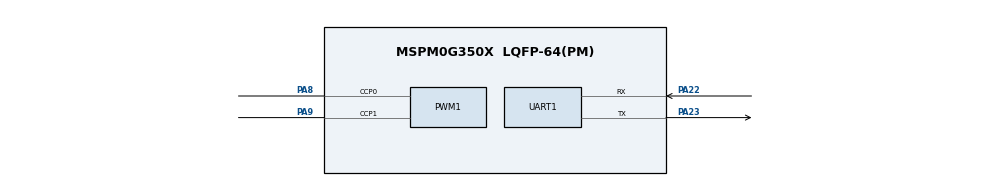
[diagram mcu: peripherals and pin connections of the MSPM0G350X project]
/**
 * @cliArgs --device "MSPM0G350X" --part "Default" --package "LQFP-64(PM)" --product "mspm0_sdk@2.10.00.04"
 * @versions {"tool":"1.26.2+4477"}
 */

/**
 * Import the modules used in this configuration.
 */
const GPIO   = scripting.addModule("/ti/driverlib/GPIO", {}, false);
const GPIO1  = GPIO.addInstance();
const GPIO2  = GPIO.addInstance();
const GPIO3  = GPIO.addInstance();
const GPIO4  = GPIO.addInstance();
const GPIO5  = GPIO.addInstance();
const GPIO6  = GPIO.addInstance();
const GPIO7  = GPIO.addInstance();
const GPIO8  = GPIO.addInstance();
const GPIO9  = GPIO.addInstance();
const GPIO10 = GPIO.addInstance();
const GPIO11 = GPIO.addInstance();
const GPIO12 = GPIO.addInstance();
const GPIO13 = GPIO.addInstance();
const GPIO14 = GPIO.addInstance();
const GPIO15 = GPIO.addInstance();
const GPIO16 = GPIO.addInstance();
const GPIO17 = GPIO.addInstance();
const GPIO18 = GPIO.addInstance();
const GPIO19 = GPIO.addInstance();
const GPIO20 = GPIO.addInstance();
const GPIO21 = GPIO.addInstance();
const PWM    = scripting.addModule("/ti/driverlib/PWM", {}, false);
const PWM1   = PWM.addInstance();
const SYSCTL = scripting.addModule("/ti/driverlib/SYSCTL");
const UART   = scripting.addModule("/ti/driverlib/UART", {}, false);
const UART1  = UART.addInstance();

/**
 * Write custom configuration values to the imported modules.
 */
GPIO1.$name                         = "GPIO_GRP_0";
GPIO1.port                          = "PORTB";
GPIO1.associatedPins[0].$name       = "PIN_2";
GPIO1.associatedPins[0].assignedPin = "2";

const Board = scripting.addModule("/ti/driverlib/Board", {}, false);

GPIO2.$name                         = "GPIO_GRP_1";
GPIO2.port                          = "PORTB";
GPIO2.associatedPins[0].$name       = "PIN_3";
GPIO2.associatedPins[0].assignedPin = "3";

GPIO3.$name                         = "GPIO_GRP_2";
GPIO3.port                          = "PORTB";
GPIO3.associatedPins[0].$name       = "PIN_6";
GPIO3.associatedPins[0].assignedPin = "6";

GPIO4.$name                         = "GPIO_GRP_3";
GPIO4.port                          = "PORTB";
GPIO4.associatedPins[0].$name       = "PIN_7";
GPIO4.associatedPins[0].assignedPin = "7";

GPIO5.port                          = "PORTA";
GPIO5.$name                         = "ENCODER_LEFTA";
GPIO5.associatedPins[0].direction   = "INPUT";
GPIO5.associatedPins[0].$name       = "PIN_0";
GPIO5.associatedPins[0].assignedPin = "0";
GPIO5.associatedPins[0].interruptEn = true;
GPIO5.associatedPins[0].polarity    = "RISE";

GPIO6.port                          = "PORTA";
GPIO6.$name                         = "ENCODER_LEFTB";
GPIO6.associatedPins[0].$name       = "PIN_1";
GPIO6.associatedPins[0].assignedPin = "1";
GPIO6.associatedPins[0].direction   = "INPUT";

GPIO7.port                          = "PORTA";
GPIO7.$name                         = "ENCODER_RIGHTA";
GPIO7.associatedPins[0].$name       = "PIN_26";
GPIO7.associatedPins[0].direction   = "INPUT";
GPIO7.associatedPins[0].interruptEn = true;
GPIO7.associatedPins[0].polarity    = "RISE";
GPIO7.associatedPins[0].assignedPin = "26";

GPIO8.port                          = "PORTA";
GPIO8.$name                         = "ENCODER_RIGHTB";
GPIO8.associatedPins[0].$name       = "PIN_27";
GPIO8.associatedPins[0].direction   = "INPUT";
GPIO8.associatedPins[0].assignedPin = "27";

GPIO9.port                          = "PORTB";
GPIO9.$name                         = "GRAY_L3";
GPIO9.associatedPins[0].direction   = "INPUT";
GPIO9.associatedPins[0].$name       = "PIN_24";
GPIO9.associatedPins[0].assignedPin = "24";

GPIO10.$name                         = "GRAY_L2";
GPIO10.port                          = "PORTB";
GPIO10.associatedPins[0].direction   = "INPUT";
GPIO10.associatedPins[0].$name       = "PIN_20";
GPIO10.associatedPins[0].assignedPin = "20";

GPIO11.$name                         = "GRAY_L1";
GPIO11.port                          = "PORTB";
GPIO11.associatedPins[0].direction   = "INPUT";
GPIO11.associatedPins[0].assignedPin = "19";
GPIO11.associatedPins[0].$name       = "PIN_19";

GPIO12.$name                         = "GRAY_M";
GPIO12.port                          = "PORTB";
GPIO12.associatedPins[0].$name       = "PIN_18";
GPIO12.associatedPins[0].assignedPin = "18";
GPIO12.associatedPins[0].direction   = "INPUT";

GPIO13.$name                          = "LED";
GPIO13.port                           = "PORTA";
GPIO13.associatedPins[0].$name        = "PIN_12";
GPIO13.associatedPins[0].assignedPin  = "12";
GPIO13.associatedPins[0].initialValue = "SET";

GPIO14.port                           = "PORTA";
GPIO14.$name                          = "BUZZER";
GPIO14.associatedPins[0].$name        = "PIN_13";
GPIO14.associatedPins[0].assignedPin  = "13";
GPIO14.associatedPins[0].initialValue = "SET";

GPIO15.$name                         = "GRAY_R1";
GPIO15.port                          = "PORTA";
GPIO15.associatedPins[0].assignedPin = "18";
GPIO15.associatedPins[0].$name       = "PINA_18";
GPIO15.associatedPins[0].direction   = "INPUT";

GPIO16.$name                         = "GRAY_R2";
GPIO16.port                          = "PORTA";
GPIO16.associatedPins[0].$name       = "PIN_17";
GPIO16.associatedPins[0].direction   = "INPUT";
GPIO16.associatedPins[0].assignedPin = "17";

GPIO17.$name                         = "GRAY_R3";
GPIO17.port                          = "PORTA";
GPIO17.associatedPins[0].$name       = "PIN_16";
GPIO17.associatedPins[0].direction   = "INPUT";
GPIO17.associatedPins[0].assignedPin = "16";

GPIO18.$name                              = "KEY1";
GPIO18.port                               = "PORTA";
GPIO18.associatedPins[0].direction        = "INPUT";
GPIO18.associatedPins[0].$name            = "PIN_21";
GPIO18.associatedPins[0].assignedPin      = "21";
GPIO18.associatedPins[0].internalResistor = "PULL_UP";

GPIO19.$name                              = "KEY2";
GPIO19.port                               = "PORTA";
GPIO19.associatedPins[0].direction        = "INPUT";
GPIO19.associatedPins[0].internalResistor = "PULL_UP";
GPIO19.associatedPins[0].assignedPin      = "24";
GPIO19.associatedPins[0].$name            = "PINA_24";

GPIO20.$name                              = "KEY3";
GPIO20.port                               = "PORTA";
GPIO20.associatedPins[0].direction        = "INPUT";
GPIO20.associatedPins[0].$name            = "PIN_02";
GPIO20.associatedPins[0].assignedPin      = "02";
GPIO20.associatedPins[0].internalResistor = "PULL_DOWN";

GPIO21.$name                         = "KEY4";
GPIO21.port                          = "PORTA";
GPIO21.associatedPins[0].direction   = "INPUT";
GPIO21.associatedPins[0].$name       = "PIN_28";
GPIO21.associatedPins[0].assignedPin = "28";

PWM1.$name                      = "PWM_0";
PWM1.peripheral.ccp0Pin.$assign = "PA8";
PWM1.peripheral.ccp1Pin.$assign = "PA9";
PWM1.PWM_CHANNEL_0.$name        = "ti_driverlib_pwm_PWMTimerCC0";
PWM1.PWM_CHANNEL_1.$name        = "ti_driverlib_pwm_PWMTimerCC1";
PWM1.ccp0PinConfig.$name        = "ti_driverlib_gpio_GPIOPinGeneric0";
PWM1.ccp1PinConfig.$name        = "ti_driverlib_gpio_GPIOPinGeneric1";

SYSCTL.forceDefaultClkConfig = true;

UART1.$name                            = "UART_2";
UART1.targetBaudRate                   = 115200;
UART1.peripheral.rxPin.$assign         = "PA22";
UART1.peripheral.txPin.$assign         = "PA23";
UART1.txPinConfig.$name                = "ti_driverlib_gpio_GPIOPinGeneric2";
UART1.txPinConfig.direction            = scripting.forceWrite("OUTPUT");
UART1.txPinConfig.hideOutputInversion  = scripting.forceWrite(false);
UART1.txPinConfig.onlyInternalResistor = scripting.forceWrite(false);
UART1.txPinConfig.passedPeripheralType = scripting.forceWrite("Digital");
UART1.rxPinConfig.$name                = "ti_driverlib_gpio_GPIOPinGeneric3";
UART1.rxPinConfig.hideOutputInversion  = scripting.forceWrite(false);
UART1.rxPinConfig.onlyInternalResistor = scripting.forceWrite(false);
UART1.rxPinConfig.passedPeripheralType = scripting.forceWrite("Digital");

/**
 * Pinmux solution for unlocked pins/peripherals. This ensures that minor changes to the automatic solver in a future
 * version of the tool will not impact the pinmux you originally saw.  These lines can be completely deleted in order to
 * re-solve from scratch.
 */
GPIO1.associatedPins[0].pin.$suggestSolution  = "PB2";
Board.peripheral.$suggestSolution             = "DEBUGSS";
Board.peripheral.swclkPin.$suggestSolution    = "PA20";
Board.peripheral.swdioPin.$suggestSolution    = "PA19";
GPIO2.associatedPins[0].pin.$suggestSolution  = "PB3";
GPIO3.associatedPins[0].pin.$suggestSolution  = "PB6";
GPIO4.associatedPins[0].pin.$suggestSolution  = "PB7";
GPIO5.associatedPins[0].pin.$suggestSolution  = "PA0";
GPIO6.associatedPins[0].pin.$suggestSolution  = "PA1";
GPIO7.associatedPins[0].pin.$suggestSolution  = "PA26";
GPIO8.associatedPins[0].pin.$suggestSolution  = "PA27";
GPIO9.associatedPins[0].pin.$suggestSolution  = "PB24";
GPIO10.associatedPins[0].pin.$suggestSolution = "PB20";
GPIO11.associatedPins[0].pin.$suggestSolution = "PB19";
GPIO12.associatedPins[0].pin.$suggestSolution = "PB18";
GPIO13.associatedPins[0].pin.$suggestSolution = "PA12";
GPIO14.associatedPins[0].pin.$suggestSolution = "PA13";
GPIO15.associatedPins[0].pin.$suggestSolution = "PA18";
GPIO16.associatedPins[0].pin.$suggestSolution = "PA17";
GPIO17.associatedPins[0].pin.$suggestSolution = "PA16";
GPIO18.associatedPins[0].pin.$suggestSolution = "PA21";
GPIO19.associatedPins[0].pin.$suggestSolution = "PA24";
GPIO20.associatedPins[0].pin.$suggestSolution = "PA2";
GPIO21.associatedPins[0].pin.$suggestSolution = "PA28";
PWM1.peripheral.$suggestSolution              = "TIMA0";
SYSCTL.peripheral.$suggestSolution            = "SYSCTL";
UART1.peripheral.$suggestSolution             = "UART2";
